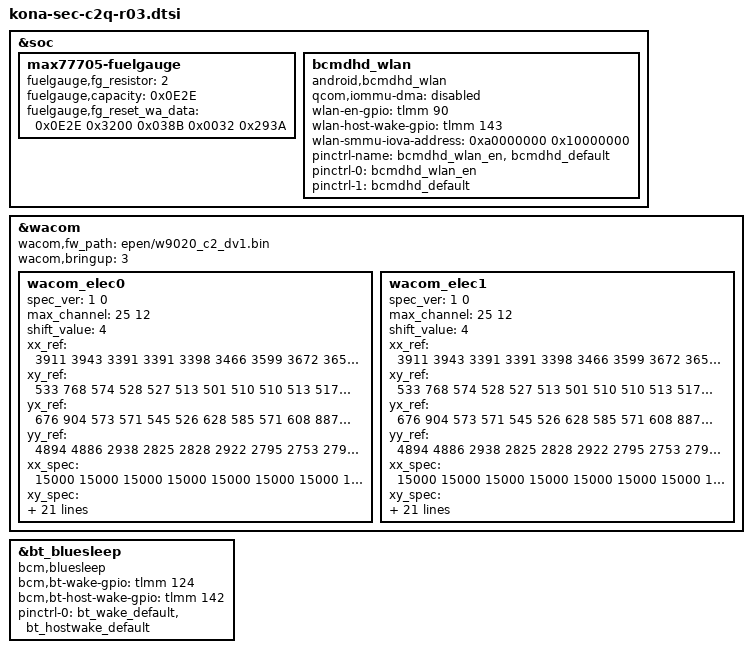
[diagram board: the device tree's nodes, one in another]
/* Copyright (c) 2020, The Linux Foundation. All rights reserved.
 *
 * This program is free software; you can redistribute it and/or modify
 * it under the terms of the GNU General Public License version 2 and
 * only version 2 as published by the Free Software Foundation.
 *
 * This program is distributed in the hope that it will be useful,
 * but WITHOUT ANY WARRANTY; without even the implied warranty of
 * MERCHANTABILITY or FITNESS FOR A PARTICULAR PURPOSE.  See the
 * GNU General Public License for more details.
 */

#include "kona-sec-c2q-r01.dtsi"
#include "kona-sec-c2q-pinctrl-r03.dtsi"
#include "../drivers/fingerprint-sensor_c2q_r03.dtsi"

&soc {
	max77705-fuelgauge {
		fuelgauge,fg_resistor = <2>;
		fuelgauge,capacity = <0x0E2E>; /* capacity = fullcapnom = DesignCap */
		fuelgauge,fg_reset_wa_data = <0x0E2E  0x3200 0x038B 0x0032 0x293A>; /* fullcapnom(=capacity), dPacc, dQacc,  rcomp0, tempco */
	};

	bcmdhd_wlan {
		qcom,iommu-dma = "disabled";
		compatible = "android,bcmdhd_wlan";
		wlan-en-gpio = <&tlmm 90 0>;
		wlan-host-wake-gpio = <&tlmm 143 0>;
		wlan-smmu-iova-address = <0xa0000000 0x10000000>;
		pinctrl-name = "bcmdhd_wlan_en","bcmdhd_default";
		pinctrl-0 = <&bcmdhd_wlan_en>;
		pinctrl-1 = <&bcmdhd_default>;
		status = "ok";
	};
};

&wacom {
	wacom,fw_path = "epen/w9020_c2_dv1.bin";
	wacom,bringup = <3>;	// force update
	/delete-node/ wacom_elec0;
	/delete-node/ wacom_elec1;
	wacom_elec0 {
		spec_ver = <1 0>; /* major minor */
		max_channel = <25 12>; /* x y */
		shift_value = <4>;

		xx_ref = /bits/ 64 <3911 3943 3391 3391 3398 3466 3599 3672 3651 3734 3750 3757 3693 3785 3937 4021 4032 4068 4053 4046 3943 4032 4264 5179 5199>;
		xy_ref = /bits/ 64 <533 768 574 528 527 513 501 510 510 513 517 516 517 521 525 532 542 515 512 499 495 522 585 884 695>;
		yx_ref = /bits/ 64 <676 904 573 571 545 526 628 585 571 608 887 678>;
		yy_ref = /bits/ 64 <4894 4886 2938 2825 2828 2922 2795 2753 2794 2755 4848 4839>;

		xx_spec = /bits/ 64 <15000 15000 15000 15000 15000 15000 15000 15000 15000 15000 15000 15000 15000 15000 15000 15000 15000 15000 15000 15000 15000 15000 15000 15000 15000>;
		xy_spec = /bits/ 64 <5000 5000 5000 5000 5000 5000 5000 5000 5000 5000 5000 5000 5000 5000 5000 5000 5000 5000 5000 5000 5000 5000 5000 5000 5000>;
		yx_spec = /bits/ 64 <5000 5000 5000 5000 5000 5000 5000 5000 5000 5000 5000 5000>;
		yy_spec = /bits/ 64 <15000 15000 15000 15000 15000 15000 15000 15000 15000 15000 15000 15000>;

		rxx_ref = /bits/ 64 <10000 10000 10000 10000 10000 10000 10000 10000 10000 10000 10000 10000 10000 10000 10000 10000 10000 10000 10000 10000 10000 10000 10000 10000 10000>;
		rxy_ref = /bits/ 64 <10000 10000 10000 10000 10000 10000 10000 10000 10000 10000 10000 10000 10000 10000 10000 10000 10000 10000 10000 10000 10000 10000 10000 10000 10000>;
		ryx_ref = /bits/ 64 <10000 10000 10000 10000 10000 10000 10000 10000 10000 10000 10000 10000>;
		ryy_ref = /bits/ 64 <10000 10000 10000 10000 10000 10000 10000 10000 10000 10000 10000 10000>;

		drxx_spec = /bits/ 64 <10000 10000 10000 10000 10000 10000 10000 10000 10000 10000 10000 10000 10000 10000 10000 10000 10000 10000 10000 10000 10000 10000 10000 10000 10000>;
		drxy_spec = /bits/ 64 <10000 10000 10000 10000 10000 10000 10000 10000 10000 10000 10000 10000 10000 10000 10000 10000 10000 10000 10000 10000 10000 10000 10000 10000 10000>;
		dryx_spec = /bits/ 64 <10000 10000 10000 10000 10000 10000 10000 10000 10000 10000 10000 10000>;
		dryy_spec = /bits/ 64 <10000 10000 10000 10000 10000 10000 10000 10000 10000 10000 10000 10000>;
	};

	/* for unit spec */
	wacom_elec1 {
		spec_ver = <1 0>; /* major minor */
		max_channel = <25 12>; /* x y */
		shift_value = <4>;

		xx_ref = /bits/ 64 <3911 3943 3391 3391 3398 3466 3599 3672 3651 3734 3750 3757 3693 3785 3937 4021 4032 4068 4053 4046 3943 4032 4264 5179 5199>;
		xy_ref = /bits/ 64 <533 768 574 528 527 513 501 510 510 513 517 516 517 521 525 532 542 515 512 499 495 522 585 884 695>;
		yx_ref = /bits/ 64 <676 904 573 571 545 526 628 585 571 608 887 678>;
		yy_ref = /bits/ 64 <4894 4886 2938 2825 2828 2922 2795 2753 2794 2755 4848 4839>;

		xx_spec = /bits/ 64 <15000 15000 15000 15000 15000 15000 15000 15000 15000 15000 15000 15000 15000 15000 15000 15000 15000 15000 15000 15000 15000 15000 15000 15000 15000>;
		xy_spec = /bits/ 64 <5000 5000 5000 5000 5000 5000 5000 5000 5000 5000 5000 5000 5000 5000 5000 5000 5000 5000 5000 5000 5000 5000 5000 5000 5000>;
		yx_spec = /bits/ 64 <5000 5000 5000 5000 5000 5000 5000 5000 5000 5000 5000 5000>;
		yy_spec = /bits/ 64 <15000 15000 15000 15000 15000 15000 15000 15000 15000 15000 15000 15000>;

		rxx_ref = /bits/ 64 <10000 10000 10000 10000 10000 10000 10000 10000 10000 10000 10000 10000 10000 10000 10000 10000 10000 10000 10000 10000 10000 10000 10000 10000 10000>;
		rxy_ref = /bits/ 64 <10000 10000 10000 10000 10000 10000 10000 10000 10000 10000 10000 10000 10000 10000 10000 10000 10000 10000 10000 10000 10000 10000 10000 10000 10000>;
		ryx_ref = /bits/ 64 <10000 10000 10000 10000 10000 10000 10000 10000 10000 10000 10000 10000>;
		ryy_ref = /bits/ 64 <10000 10000 10000 10000 10000 10000 10000 10000 10000 10000 10000 10000>;

		drxx_spec = /bits/ 64 <10000 10000 10000 10000 10000 10000 10000 10000 10000 10000 10000 10000 10000 10000 10000 10000 10000 10000 10000 10000 10000 10000 10000 10000 10000>;
		drxy_spec = /bits/ 64 <10000 10000 10000 10000 10000 10000 10000 10000 10000 10000 10000 10000 10000 10000 10000 10000 10000 10000 10000 10000 10000 10000 10000 10000 10000>;
		dryx_spec = /bits/ 64 <10000 10000 10000 10000 10000 10000 10000 10000 10000 10000 10000 10000>;
		dryy_spec = /bits/ 64 <10000 10000 10000 10000 10000 10000 10000 10000 10000 10000 10000 10000>;
	};
};

&bt_bluesleep {
       compatible = "bcm,bluesleep";
       bcm,bt-wake-gpio = <&tlmm 124 0>;
       bcm,bt-host-wake-gpio = <&tlmm 142 0>;
       pinctrl-names = "default";
       pinctrl-0 = <&bt_wake_default &bt_hostwake_default>;
       status = "ok";
};
